AUTOSAR XML (schema 4.0)
package /Battery_EV_Components
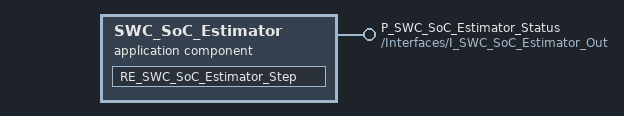
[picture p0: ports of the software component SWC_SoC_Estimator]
  application sw component type SWC_SoC_Estimator  # AUTOSAR Application SWC SWC_SoC_Estimator for Battery EV Safety
    provide port P_SWC_SoC_Estimator_Status: provided-interface=/Interfaces/I_SWC_SoC_Estimator_Out
    behavior SWC_SoC_Estimator_Behavior
      runnable RE_SWC_SoC_Estimator_Step: symbol=SWC_SoC_Estimator_Step
  sender receiver interface I_SWC_SoC_Estimator_Out
    data DE_SWC_SoC_Estimator_Health: type=/AUTOSAR/Platform/uint32
